# STM32F479 register map
File version: 2.0
CPU: CM4 r0p1, little endian, MPU, FPU, 4 interrupt priority bits
Registers are 32-bit, read-write, reset 0x0 unless marked. A register's access mark holds for its fields unless they carry their own. Offsets are from the block's base; [hi:lo] are bit positions; {n}, {i} and the like mark numbered series; 'fields as' and 'values as' point back to an identical list; <NAME> marks a mode.

## DSIHOST (part 2 of 2)
Base 0x40016C00
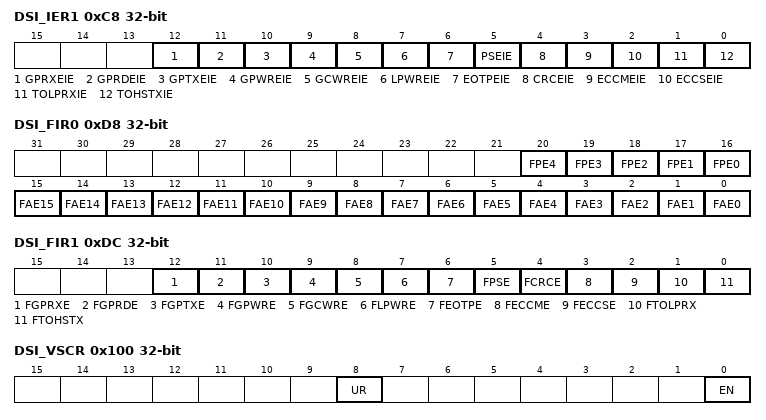
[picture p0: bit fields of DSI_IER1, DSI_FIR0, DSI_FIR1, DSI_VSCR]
0xC8 DSI_IER1 — DSI Host interrupt enable register 1
  [12] GPRXEIE — Generic payload receive error interrupt enable This bit enables the interrupt generation on generic payload receive error.
    0=Interrupt on generic payload receive error disabled; 1=Interrupt on generic payload receive error enabled
  [11] GPRDEIE — Generic payload read error interrupt enable This bit enables the interrupt generation on generic payload read error.
    0=Interrupt on generic payload read error disabled; 1=Interrupt on generic payload read error enabled
  [10] GPTXEIE — Generic payload transmit error interrupt enable This bit enables the interrupt generation on generic payload transmit error.
    0=Interrupt on generic payload transmit error disabled; 1=Interrupt on generic payload transmit error enabled
  [9] GPWREIE — Generic payload write error interrupt enable This bit enables the interrupt generation on generic payload write error.
    0=Interrupt on generic payload write error disabled; 1=Interrupt on generic payload write error enabled
  [8] GCWREIE — Generic command write error interrupt enable This bit enables the interrupt generation on generic command write error.
    0=Interrupt on generic command write error disabled; 1=Interrupt on generic command write error enabled
  [7] LPWREIE — LTDC payload write error interrupt enable This bit enables the interrupt generation on LTDC payload write error.
    0=Interrupt on LTDC payload write error disabled; 1=Interrupt on LTDC payload write error enabled
  [6] EOTPEIE — EoTp error interrupt enable This bit enables the interrupt generation on EoTp error.
    0=Interrupt on EoTp error disabled; 1=Interrupt on EoTp error enabled
  [5] PSEIE — Packet size error interrupt enable This bit enables the interrupt generation on packet size error.
    0=Interrupt on packet size error disabled; 1=Interrupt on packet size error enabled
  [4] CRCEIE — CRC error interrupt enable This bit enables the interrupt generation on CRC error.
    0=Interrupt on CRC error disabled; 1=Interrupt on CRC error enabled
  [3] ECCMEIE — ECC multi-bit error interrupt enable This bit enables the interrupt generation on ECC multi-bit error.
    0=Interrupt on ECC multi-bit error disabled; 1=Interrupt on ECC multi-bit error enabled
  [2] ECCSEIE — ECC single-bit error interrupt enable This bit enables the interrupt generation on ECC single-bit error.
    0=Interrupt on ECC single-bit error disabled; 1=Interrupt on ECC single-bit error enabled
  [1] TOLPRXIE — Timeout low-power reception interrupt enable This bit enables the interrupt generation on timeout low-power reception.
    0=Interrupt on timeout low-power reception disabled; 1=Interrupt on timeout low-power reception enabled
  [0] TOHSTXIE — Timeout high-speed transmission interrupt enable This bit enables the interrupt generation on timeout high-speed transmission .
    0=Interrupt on timeout high-speed transmission disabled; 1=Interrupt on timeout high-speed transmission enabled
0xD8 DSI_FIR0 wo — DSI Host force interrupt register 0
  [n+16] FPE{n} (n=0..4) — Force PHY error {n} Writing one to this bit forces a PHY error {n}.
  [n] FAE{n} (n=0..15) — Force acknowledge error {n} Writing one to this bit forces an acknowledge error {n}.
0xDC DSI_FIR1 wo — DSI Host force interrupt register 1
  [12] FGPRXE — Force generic payload receive error Writing one to this bit forces a generic payload receive error.
  [11] FGPRDE — Force generic payload read error Writing one to this bit forces a generic payload read error.
  [10] FGPTXE — Force generic payload transmit error Writing one to this bit forces a generic payload transmit error.
  [9] FGPWRE — Force generic payload write error Writing one to this bit forces a generic payload write error.
  [8] FGCWRE — Force generic command write error Writing one to this bit forces a generic command write error.
  [7] FLPWRE — Force LTDC payload write error Writing one to this bit forces a LTDC payload write error.
  [6] FEOTPE — Force EoTp error Writing one to this bit forces a EoTp error.
  [5] FPSE — Force packet size error Writing one to this bit forces a packet size error.
  [4] FCRCE — Force CRC error Writing one to this bit forces a CRC error.
  [3] FECCME — Force ECC multi-bit error Writing one to this bit forces a ECC multi-bit error.
  [2] FECCSE — Force ECC single-bit error Writing one to this bit forces a ECC single-bit error.
  [1] FTOLPRX — Force timeout low-power reception Writing one to this bit forces a timeout low-power reception.
  [0] FTOHSTX — Force timeout high-speed transmission Writing one to this bit forces a timeout high-speed transmission.
0x100 DSI_VSCR — DSI Host video shadow control register
  [8] UR — Update register When set to 1, the LTDC registers are copied to the auxiliary registers. After copying, this bit is auto cleared.
    0=No update requested; 1=Register update requested
  [0] EN — Enable When set to 1, DSI Host LTDC interface receives the active configuration from the auxiliary registers. When this bit is set along with the UR bit, the auxiliary registers are automatically updated.
    0=Register update is disabled; 1=Register update is enabled
0x10C DSI_LCVCIDR — DSI Host LTDC current VCID register
  [1:0] VCID — Virtual channel ID This field returns the virtual channel ID for the LTDC interface.
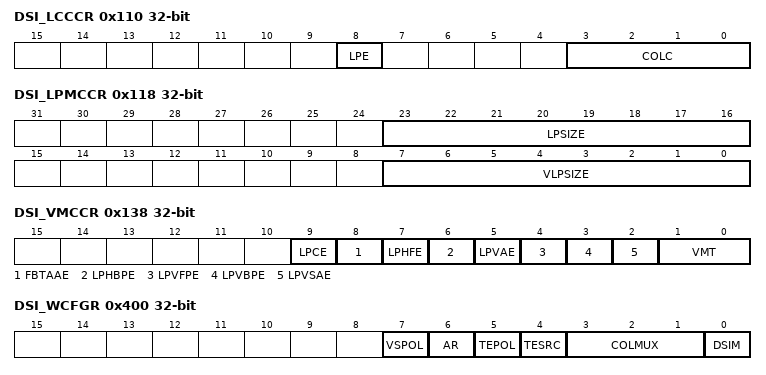
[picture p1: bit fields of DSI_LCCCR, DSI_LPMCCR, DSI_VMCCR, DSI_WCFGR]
0x110 DSI_LCCCR ro — DSI Host LTDC current color coding register
  [8] LPE — Loosely packed enable This bit returns the current state of the loosely packed variant to 18-bit configurations.
    0=Loosely packed variant disabled; 1=Loosely packed variant enabled
  [3:0] COLC — Color coding This field returns the current LTDC interface color coding. If LTDC interface in command mode is chosen and currently works in the command mode (CMDM=1), then 0110-1111: 24-bit
    0=16-bit configuration 1; 1=16-bit configuration 2; 2=16-bit configuration 3; 3=18-bit configuration 1; 4=18-bit configuration 2; 5=24-bit
0x118 DSI_LPMCCR ro — DSI Host low-power mode current configuration register
  [23:16] LPSIZE — Largest packet size This field is returns the current size, in bytes, of the largest packet that can fit in a line during VSA, VBP and VFP regions, for the transmission of commands in low-power mode.
  [7:0] VLPSIZE — VACT largest packet size This field returns the current size, in bytes, of the largest packet that can fit in a line during VACT regions, for the transmission of commands in low-power mode.
0x138 DSI_VMCCR ro — DSI Host video mode current configuration register
  [9] LPCE — Low-power command enable This bit returns the current command transmission state in low-power mode.
    0=Command transmission in low-power mode is disabled; 1=Command transmission in low-power mode is enabled
  [8] FBTAAE — Frame BTA acknowledge enable This bit returns the current state of request for an acknowledge response at the end of a frame.
    0=Acknowledge response at the end of a frame is disabled; 1=Acknowledge response at the end of a frame is enabled
  [7] LPHFE — Low-power horizontal front-porch enable This bit returns the current state of return to low-power inside the horizontal front-porch (HFP) period when timing allows.
    0=Return to low-power inside the HFP period is disabled; 1=Return to low-power inside the HFP period is enabled
  [6] LPHBPE — Low-power horizontal back-porch enable This bit returns the current state of return to low-power inside the horizontal back-porch (HBP) period when timing allows.
    0=Return to low-power inside the HBP period is disabled; 1=Return to low-power inside the HBP period is enabled
  [5] LPVAE — Low-power vertical active enable This bit returns the current state of return to low-power inside the vertical active (VACT) period when timing allows.
    0=Return to low-power inside the VACT is disabled; 1=Return to low-power inside the VACT is enabled
  [4] LPVFPE — Low-power vertical front-porch enable This bit returns the current state of return to low-power inside the vertical front-porch (VFP) period when timing allows.
    0=Return to low-power inside the VFP is disabled; 1=Return to low-power inside the VFP is enabled
  [3] LPVBPE — Low-power vertical back-porch enable This bit returns the current state of return to low-power inside the vertical back-porch (VBP) period when timing allows.
    0=Return to low-power inside the VBP is disabled; 1=Return to low-power inside the VBP is enabled
  [2] LPVSAE — Low-power vertical sync time enable This bit returns the current state of return to low-power inside the vertical sync time (VSA) period when timing allows.
    0=Return to low-power inside the VSA is disabled; 1=Return to low-power inside the VSA is enabled
  [1:0] VMT — Video mode type This field returns the current video mode transmission type: 1x: Burst mode
    0=Non-burst with sync pulses; 1=Non-burst with sync events
0x13C DSI_VPCCR ro — DSI Host video packet current configuration register
  [13:0] VPSIZE — Video packet size This field returns the number of pixels in a single video packet.
0x140 DSI_VCCCR ro — DSI Host video chunks current configuration register
  [12:0] NUMC — Number of chunks This field returns the number of chunks being transmitted during a line period.
0x144 DSI_VNPCCR ro — DSI Host video null packet current configuration register
  [12:0] NPSIZE — Null packet size This field returns the number of bytes inside a null packet.
0x148 DSI_VHSACCR ro — DSI Host video HSA current configuration register
  [11:0] HSA — Horizontal synchronism active duration This fields returns the horizontal synchronism active period in lane byte clock cycles.
0x14C DSI_VHBPCCR ro — DSI Host video HBP current configuration register
  [11:0] HBP — Horizontal back-porch duration This field returns the horizontal back-porch period in lane byte clock cycles.
0x150 DSI_VLCCR ro — DSI Host video line current configuration register
  [14:0] HLINE — Horizontal line duration This field returns the current total of the horizontal line period (HSA+HBP+HACT+HFP) counted in lane byte clock cycles.
0x154 DSI_VVSACCR ro — DSI Host video VSA current configuration register
  [9:0] VSA — Vertical synchronism active duration This field returns the current vertical synchronism active period measured in number of horizontal lines.
0x158 DSI_VVBPCCR ro — DSI Host video VBP current configuration register
  [9:0] VBP — Vertical back-porch duration This field returns the current vertical back-porch period measured in number of horizontal lines.
0x15C DSI_VVFPCCR ro — DSI Host video VFP current configuration register
  [9:0] VFP — Vertical front-porch duration This field returns the current vertical front-porch period measured in number of horizontal lines.
0x160 DSI_VVACCR ro — DSI Host video VA current configuration register
  [13:0] VA — Vertical active duration This field returns the current vertical active period measured in number of horizontal lines.
0x400 DSI_WCFGR — DSI Wrapper configuration register
  [7] VSPOL — VSync polarity This bit selects the VSync edge on which the LTDC is halted. This bit must only be changed when DSI is stopped (DSI_WCR.DSIEN = 0 and DSI_CR.EN=0).
    0=LTDC halted on a falling edge; 1=LTDC halted on a rising edge
  [6] AR — Automatic refresh This bit selects the refresh mode in DBI mode. This bit must only be changed when DSI Host is stopped (DSI_CR.EN = 0).
    0=automatic refresh mode disabled; 1=automatic refresh mode enabled
  [5] TEPOL — TE polarity This bit selects the polarity of the external pin tearing effect (TE) source. This bit must only be changed when DSI Host is stopped (DSI_CR.EN = 0).
    0=rising edge; 1=falling edge
  [4] TESRC — TE source This bit selects the tearing effect (TE) source. This bit must only be changed when DSI Host is stopped (DSI_CR.EN = 0).
    0=DSI Link; 1=External pin
  [3:1] COLMUX — Color multiplexing This bit selects the color multiplexing used by DSI Host. This field must only be changed when DSI is stopped (DSI_WCR.DSIEN = 0 and DSI_CR.EN=0).
    values as DSI_LCCCR.COLC
  [0] DSIM — DSI mode This bit selects the mode for the video transmission. This bit must only be changed when DSI Host is stopped (DSI_CR.EN = 0).
    0=Video mode; 1=Adapted command mode
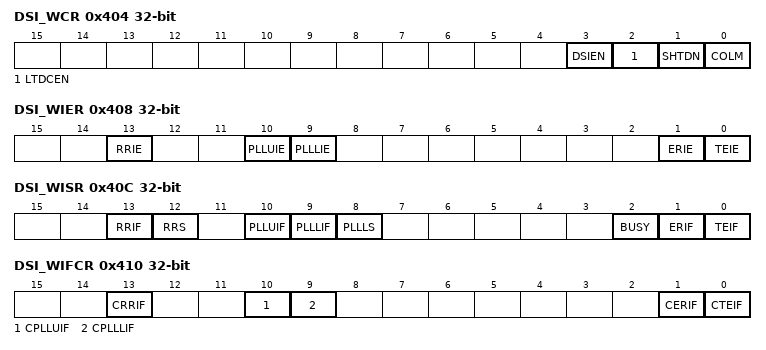
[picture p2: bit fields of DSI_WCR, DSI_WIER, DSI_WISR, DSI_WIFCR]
0x404 DSI_WCR — DSI Wrapper control register
  [3] DSIEN — DSI enable This bit enables the DSI Wrapper.
    0=DSI disabled; 1=DSI enabled
  [2] LTDCEN — LTDC enable This bit enables the LTDC for a frame transfer in adapted command mode.
    0=LTDC disabled; 1=LTDC enabled
  [1] SHTDN — Shutdown This bit controls the display shutdown in video mode.
    0=display ON; 1=display OFF
  [0] COLM — Color mode This bit controls the display color mode in video mode.
    0=Full color mode; 1=Eight color mode
0x408 DSI_WIER — DSI Wrapper interrupt enable register
  [13] RRIE — Regulator ready interrupt enable This bit enables the regulator ready interrupt.
    0=Regulator ready interrupt disabled; 1=Regulator ready interrupt enabled
  [10] PLLUIE — PLL unlock interrupt enable This bit enables the PLL unlock interrupt.
    0=PLL unlock interrupt disabled; 1=PLL unlock interrupt enabled
  [9] PLLLIE — PLL lock interrupt enable This bit enables the PLL lock interrupt.
    0=PLL lock interrupt disabled; 1=PLL lock interrupt enabled
  [1] ERIE — End of refresh interrupt enable This bit enables the end of refresh interrupt.
    0=End of refresh interrupt disabled; 1=End of refresh interrupt enabled
  [0] TEIE — Tearing effect interrupt enable This bit enables the tearing effect interrupt.
    0=Tearing effect interrupt disabled; 1=Tearing effect interrupt enabled
0x40C DSI_WISR ro — DSI Wrapper interrupt and status register
  [13] RRIF — Regulator ready interrupt flag This bit is set when the regulator becomes ready.
    0=No regulator ready event occurred; 1=Regulator ready event occurred
  [12] RRS — Regulator ready status This bit gives the status of the regulator.
    0=Regulator is not ready; 1=Regulator is ready
  [10] PLLUIF — PLL unlock interrupt flag This bit is set when the PLL becomes unlocked.
    0=No PLL unlock event occurred; 1=PLL unlock event occurred
  [9] PLLLIF — PLL lock interrupt flag This bit is set when the PLL becomes locked.
    0=No PLL lock event occurred; 1=PLL lock event occurred
  [8] PLLLS — PLL lock status This bit is set when the PLL is locked and cleared when it is unlocked.
    0=PLL is unlocked; 1=PLL is locked
  [2] BUSY — Busy flag This bit is set when the transfer of a frame in adapted command mode is ongoing.
    0=No transfer on going; 1=Transfer on going
  [1] ERIF — End of refresh interrupt flag This bit is set when the transfer of a frame in adapted command mode is finished.
    0=No end of refresh event occurred; 1=End of refresh event occurred
  [0] TEIF — Tearing effect interrupt flag This bit is set when a tearing effect event occurs.
    0=No tearing effect event occurred; 1=Tearing effect event occurred
0x410 DSI_WIFCR wo — DSI Wrapper interrupt flag clear register
  [13] CRRIF — Clear regulator ready interrupt flag Write 1 clears the RRIF flag in the DSI_WSR register.
  [10] CPLLUIF — Clear PLL unlock interrupt flag Write 1 clears the PLLUIF flag in the DSI_WSR register.
  [9] CPLLLIF — Clear PLL lock interrupt flag Write 1 clears the PLLLIF flag in the DSI_WSR register.
  [1] CERIF — Clear end of refresh interrupt flag Write 1 clears the ERIF flag in the DSI_WSR register.
  [0] CTEIF — Clear tearing effect interrupt flag Write 1 clears the TEIF flag in the DSI_WSR register.
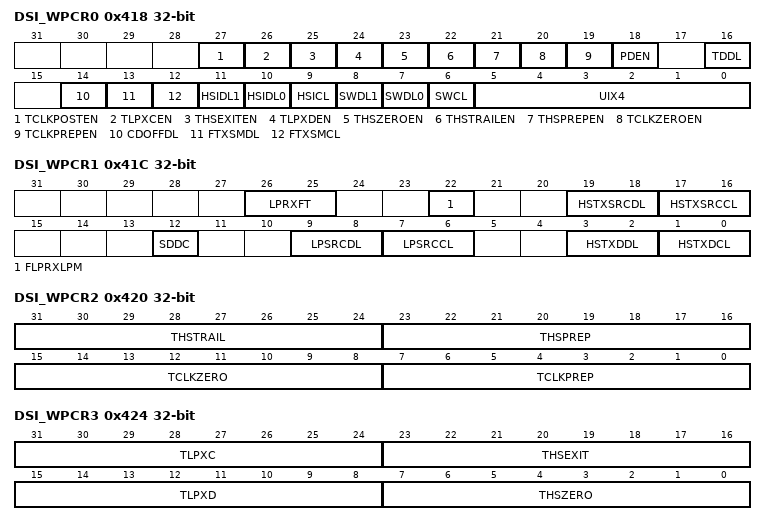
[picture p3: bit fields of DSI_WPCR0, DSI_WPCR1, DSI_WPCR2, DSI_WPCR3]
0x418 DSI_WPCR0 — DSI Wrapper PHY configuration register 0
  [27] TCLKPOSTEN — Custom time for t<sub>CLK-POST</sub> enable This bit enables the manual programming of t<sub>CLK-POST </sub>duration in the D-PHY. The desired value must be programmed in the TCLKPOST field of the DSI_WPCR4 register.
    0=Default value is used for t<sub>CLKPOST</sub>; 1=Programmable value is used for t<sub>CLKPOST</sub>
  [26] TLPXCEN — Custom time for t<sub>LPX</sub> for clock lane enable This bit enables the manual programming of t<sub>LPX</sub> duration for the clock lane in the D-PHY. The desired value must be programmed in the TLPXC field of the DSI_WPCR3 register.
    0=Default value is used for t<sub>LPX</sub> for the clock lane; 1=Programmable value is used for t<sub>LPX</sub> for the clock lane
  [25] THSEXITEN — Custom time for t<sub>HS-EXIT</sub> enable This bit enables the manual programming of t<sub>HS-EXIT </sub>duration in the D-PHY. The desired value must be programmed in the THSEXIT field of the DSI_WPCR3 register.
    0=Default value is used for t<sub>HS-EXIT</sub>; 1=Programmable value is used for t<sub>HS-EXIT</sub>
  [24] TLPXDEN — Custom time for t<sub>LPX</sub> for data lanes enable This bit enables the manual programming of T<sub>LPX </sub>duration for the data lanes in the D-PHY. The desired value must be programmed in the TLPXD field of the DSI_WPCR3 register.
    0=Default value is used for T<sub>LPX</sub> for the data lanes; 1=Programmable value is used for T<sub>LPX</sub> for the data lanes
  [23] THSZEROEN — Custom time for t<sub>HS-ZERO</sub> enable This bit enables the manual programming of t<sub>HS-ZERO </sub>duration in the D-PHY. The desired value must be programmed in the THSZERO field of the DSI_WPCR3 register.
    0=Default value is used for t<sub>HS-ZERO</sub>; 1=Programmable value is used for t<sub>HS-ZERO</sub>
  [22] THSTRAILEN — Custom time for t<sub>HS-TRAIL</sub> enable This bit enables the manual programming of T<sub>HS-TRAIL </sub>duration in the D-PHY. The desired value must be programmed in the THSRAIL field of the DSI_WPCR2 register.
    0=Default value is used for T<sub>HS-TRAIL</sub>; 1=Programmable value is used for T<sub>HS-TRAIL</sub>
  [21] THSPREPEN — Custom time for t<sub>HS-PREPARE</sub> enable This bit enables the manual programming of t<sub>HS-PREPARE </sub>duration in the D-PHY. The desired value must be programmed in the THSPREP field of the DSI_WPCR2 register.
    0=Default value is used for t<sub>HS-PREPARE</sub>; 1=Programmable value is used for t<sub>HS-PREPARE</sub>
  [20] TCLKZEROEN — Custom time for t<sub>CLK-ZERO</sub> enable This bit enables the manual programming of t<sub>CLK-ZERO </sub>duration in the D-PHY. The desired value must be programmed in the TCLKZERO field of the DSI_WPCR2 register.
    0=Default value is used for t<sub>CLK-ZERO</sub>; 1=Programmable value is used for t<sub>CLK-ZERO</sub>
  [19] TCLKPREPEN — Custom time for t<sub>CLK-PREPARE</sub> enable This bit enables the manual programming of t<sub>CLK-PREPARE </sub>duration in the D-PHY. The desired value must be programmed in the TLKCPREP field of the DSI_WPCR2 register.
    0=Default value is used for t<sub>CLK-PREPARE</sub>; 1=Programmable value is used for t<sub>CLK-PREPARE</sub>
  [18] PDEN — Pull-down enable This bit enables a pull-down on the lane to prevent from floating states when unused.
    0=Pull-down on lanes disabled; 1=Pull-down on lanes enabled
  [16] TDDL — Turn disable data lanes This bit forces the data lane to remain in RX event if it receives a bus-turn-around request from the other side.
    0=No effect; 1=Force data lanes in RX mode after a BTA
  [14] CDOFFDL — Contention detection OFF on data lanes When only forward escape mode is used, this signal can be made high to switch off the contention detector and reduce static power consumption.
    0=Contention detection on data lane ON; 1=Contention detection on data lane OFF
  [13] FTXSMDL — Force in TX Stop mode the data lanes This bit forces the data lanes in TX stop mode. It is used to initialize a lane module in transmit mode. It causes the lane module to immediately jump to transmit control mode and to begin transmitting a stop state (LP-11). It can be used to go back in TX mode after a wrong BTA sequence.
    0=No effect; 1=Force the data lanes in TX Stop mode
  [12] FTXSMCL — Force in TX Stop mode the clock lane This bit forces the clock lane in TX stop mode. It is used to initialize a lane module in transmit mode. It causes the lane module to immediately jump to transmit control mode and to begin transmitting a stop state (LP-11). It can be used to go back in TX mode after a wrong BTA sequence.
    0=No effect; 1=Force the clock lane in TX Stop mode
  [11] HSIDL1 — Invert the high-speed data signal on data lane 1 This bit inverts the high-speed data signal on data lane 1.
    0=Normal data signal configuration; 1=Inverted data signal configuration
  [10] HSIDL0 — Invert the high-speed data signal on data lane 0 This bit inverts the high-speed data signal on clock lane.
    values as HSIDL1
  [9] HSICL — Invert high-speed data signal on clock lane This bit inverts the high-speed data signal on clock lane.
    0=Normal data configuration; 1=Inverted data configuration
  [8] SWDL1 — Swap data lane 1 pins This bit swaps the pins on clock lane.
    0=Regular clock lane pin configuration; 1=Swapped clock lane pin
  [7] SWDL0 — Swap data lane 0 pins This bit swaps the pins on data lane 0.
    values as SWDL1
  [6] SWCL — Swap clock lane pins This bit swaps the pins on clock lane.
    values as SWDL1
  [5:0] UIX4 — Unit interval multiplied by 4 This field defines the bit period in high-speed mode in unit of 0.25 ns. As an example, if the unit interval is 3 ns, a value of twelve (0x0C) must be driven to this input. This value is used to generate delays. If the period is not a multiple of 0.25 ns, the value driven must be rounded down. For example, a 600 Mbit/s link uses a unit interval of 1.667 ns, which, multiplied by four gives 6.667 ns. In this case a value of 6 (not 7) must be driven onto the ui_x4 input.
0x41C DSI_WPCR1 — DSI Wrapper PHY configuration register 1
  [26:25] LPRXFT — Low-power RX low-pass filtering tuning This signal can be used to tune the cutoff frequency of low-pass filter at the input of LPRX.
  [22] FLPRXLPM — Forces LP receiver in low-power mode This bit enables the low-power mode of LP receiver (LPRX). When set, the LPRX operates in low-power mode all the time (when this is not activated, LPRX operates in low power mode during ULPS only).
    0=No effect; 1=LPRX is forced in low-power mode
  [19:18] HSTXSRCDL — High-speed transmission slew-rate control on data lanes Slew-rate control for high-speed transmitter output. It can be used to change slew-rate of data lane HS transitions. Default value = 00.
  [17:16] HSTXSRCCL — High-speed transmission slew-rate control on clock lane Slew-rate control for high-speed transmitter output. It can be used to change slew-rate of clock lane HS transitions. Default value = 00.
  [12] SDDC — SDD control This bit switches on the additional current path to meet the SDDTx parameter defined by MIPI<sup></sup> D-PHY Specification on both clock and data lanes.
    0=No effect; 1=Activate additional current path on all lanes
  [9:8] LPSRCDL — Low-power transmission slew-rate compensation on data lanes Can be used to change slew-rate of data lane LP transitions. Default value = 00.
  [7:6] LPSRCCL — Low-power transmission slew-rate compensation on clock lane Can be used to change slew-rate of clock lane LP transitions. Default value = 00.
  [3:2] HSTXDDL — High-speed transmission delay on data lanes Delay tuner control to change delay (up to DP/DN) in data path. Can be used to change data edge transition positions with respect to clock edge on DP/DN. Default value = 00.
  [1:0] HSTXDCL — High-speed transmission delay on clock lane Delay tuner control to change delay (up to DP/DN) in clock path. Can be used to change clock edge position with respect to data bit transitions on DP/DN. Default value = 00.
0x420 DSI_WPCR2 — DSI Wrapper PHY configuration register 2
  [31:24] THSTRAIL — t<sub>HSTRAIL</sub> This field defines the t<sub>HS-TRAIL</sub> has specified in the MIPI<sup></sup> D-PHY specification. This value is used by the D-PHY when the THSTRAILEN bit of the DSI_WPCR0 is set. THSTRAIL = 2 x t<sub>HS-TRAIL</sub> expressed in ns.The default value used by the D-PHY when THSTRAILEN bit of the DSI_WPCR0 is reset is 140 (70ns+8*UI).
  [23:16] THSPREP — t<sub>HS-PREPARE</sub> This field defines the t<sub>HS-PREPARE</sub> has specified in the MIPI<sup></sup> D-PHY specification. This value is used by the D-PHY when the THSPREPEN bit of the DSI_WPCR0 is set. THSPREP = 2 x t<sub>HS-PREPARE</sub> expressed in ns.The default value used by the D-PHY when THSPREPEN bit of the DSI_WPCR0 is reset is 126 (63ns + 12*UI).
  [15:8] TCLKZERO — t<sub>CLK-ZERO</sub> This field defines the t<sub>CLK-ZERO</sub> has specified in the MIPI<sup></sup> D-PHY specification. This value is used by the D-PHY when the TCLKZEROEN bit of the DSI_WPCR0 is set. TCLKZERO = t<sub>CLK-ZERO</sub> / 2 expressed in ns.The default value used by the D-PHY when TCLKZEROEN bit of the DSI_WPCR0 is reset is 195 (390ns).
  [7:0] TCLKPREP — t<sub>CLK-PREPARE</sub> This field defines the t<sub>CLK-PREPARE</sub> has specified in the MIPI<sup></sup> D-PHY specification. This value is used by the D-PHY when the TCLKPREPEN bit of the DSI_WPCR0 is set. TCLKPREP = 2 x t<sub>CLK-PREPARE</sub> expressed in ns.The default value used by the D-PHY when TCLKPREPEN bit of the DSI_WPCR0 is reset is 120 (60ns + 20*UI).
0x424 DSI_WPCR3 — DSI Wrapper PHY configuration register 3
  [31:24] TLPXC — t<sub>LPXC</sub> for clock lane This field defines the t<sub>LPX</sub> has specified in the MIPI<sup></sup> D-PHY specification for the clock lane. This value is used by the D-PHY when the TLPXCEN bit of the DSI_WPCR1 is set. TLPXC = 2 x t<sub>LPX</sub> expressed in ns.The default value used by the D-PHY when TLPXCEN bit of the DSI_WPCR1 is reset is 100 (50ns).
  [23:16] THSEXIT — t<sub>HSEXIT</sub> This field defines the t<sub>HS-EXHigh-SpeedIT</sub> has specified in the MIPI<sup></sup> D-PHY specification. This value is used by the D-PHY when the THSEXITEN bit of the DSI_WPCR1 is set. THSEXIT = t<sub>HS-ZERO</sub> expressed in ns.The default value used by the D-PHY when THSEXITEN bit of the DSI_WPCR1 is reset is 100 (100ns).
  [15:8] TLPXD — t<sub>LPX</sub> for data lanes This field defines the t<sub>LPX</sub> has specified in the MIPI<sup></sup> D-PHY specification for the data lanes. This value is used by the D-PHY when the TLPXDEN bit of the DSI_WPCR1 is set. TLPXD = 2 x t<sub>LPX</sub> expressed in ns.The default value used by the D-PHY when TLPXDEN bit of the DSI_WPCR1 is reset is 100 (50ns).
  [7:0] THSZERO — t<sub>HS-ZERO</sub> This field defines the t<sub>HS-ZERO</sub> has specified in the MIPI<sup></sup> D-PHY specification. This value is used by the D-PHY when the THSZEROEN bit of the DSI_WPCR1 is set. THSZERO = t<sub>HS-ZERO</sub> expressed in ns.The default value used by the D-PHY when THSZEROEN bit of the DSI_WPCR1 is reset is 175, (175ns).
0x428 DSI_WPCR4 — DSI Wrapper PHY configuration register 4
  [7:0] TCLKPOST — t<sub>CLK-POST</sub> This field defines the t<sub>CLK-POST</sub> has specified in the MIPI<sup></sup> D-PHY specification. This value is used by the D-PHY when the TCLKPOSTEN bit of the DSI_WPCR0 is set. TCLKPOST = 2 x t<sub>CLK-POST</sub> expressed in ns.The default value used by the D-PHY when TCLKPOSTEN bit of the DSI_WPCR0 is reset is 200 (100ns + 120*UI).
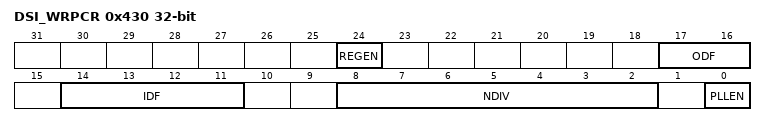
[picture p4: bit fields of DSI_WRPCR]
0x430 DSI_WRPCR — DSI Wrapper regulator and PLL control register
  [24] REGEN — Regulator enable This bit enables the DPHY regulator.
    0=regulator disabled; 1=regulator enabled
  [17:16] ODF — PLL output division factor This field configures the PLL output division factor.
    0=PLL output divided by 1; 1=PLL output divided by 2; 2=PLL output divided by 4; 3=PLL output divided by 8
  [14:11] IDF — PLL input division factor This field configures the PLL input division factor.
    0=PLL input divided by 1; {v}=PLL input divided by {v} (v=1..7)
  [8:2] NDIV — PLL loop division factor This field configures the PLL loop division factor. 10 to 125: Allowed loop division factor values Others: Reserved
  [0] PLLEN — PLL enable This bit enables the D-PHY PLL.
    0=PLL disabled; 1=PLL enabled
